CM_ "IMPORT _nissan_common.dbc";

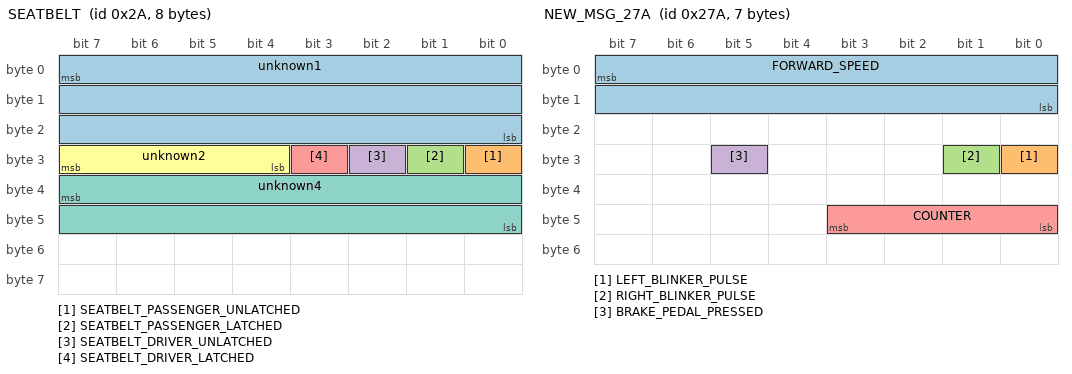
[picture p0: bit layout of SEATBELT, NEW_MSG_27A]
BO_ 42 SEATBELT: 8 XXX
 SG_ unknown1 : 7|24@0+ (1,0) [0|16777215] "" XXX
 SG_ SEATBELT_PASSENGER_UNLATCHED : 24|1@0+ (1,0) [0|1] "" XXX
 SG_ SEATBELT_PASSENGER_LATCHED : 25|1@0+ (1,0) [0|1] "" XXX
 SG_ SEATBELT_DRIVER_UNLATCHED : 26|1@0+ (1,0) [0|1] "" XXX
 SG_ SEATBELT_DRIVER_LATCHED : 27|1@1+ (1,0) [0|3] "" XXX
 SG_ unknown2 : 31|4@0+ (1,0) [0|15] "" XXX
 SG_ unknown4 : 39|16@0+ (1,0) [0|65535] "" XXX

BO_ 634 NEW_MSG_27A: 7 XXX
 SG_ FORWARD_SPEED : 7|16@0+ (0.1,0) [0|65535] "KPH" XXX
 SG_ LEFT_BLINKER_PULSE : 24|1@0+ (1,0) [0|1] "" XXX
 SG_ RIGHT_BLINKER_PULSE : 25|1@0+ (1,0) [0|1] "" XXX
 SG_ BRAKE_PEDAL_PRESSED : 29|1@0+ (1,0) [0|1] "" XXX
 SG_ COUNTER : 40|4@1+ (1,0) [0|15] "" XXX

BO_ 460 BRAKE_PEDAL: 8 XXX
 SG_ BRAKE_PEDAL : 7|8@0+ (1,0) [0|256] "" XXX

BO_ 569 CRUISE_THROTTLE: 8 XXX
 SG_ GAS_PEDAL_INVERTED : 15|8@0+ (1,0) [0|255] "" XXX
 SG_ GAS_PEDAL : 7|8@0+ (1,0) [0|255] "" XXX
 SG_ CRUISE_AVAILABLE : 17|1@0+ (1,0) [0|1] "" XXX
 SG_ unsure1 : 23|6@0+ (1,0) [0|63] "" XXX
 SG_ unsure2 : 16|1@0+ (1,0) [0|1] "" XXX
 SG_ unsure3 : 31|2@0+ (1,0) [0|3] "" XXX
 SG_ NO_BUTTON_PRESSED : 29|1@0+ (1,0) [0|1] "" XXX
 SG_ RES_BUTTON : 28|1@0+ (1,0) [0|1] "" XXX
 SG_ SET_BUTTON : 27|1@0+ (1,0) [0|1] "" XXX
 SG_ FOLLOW_DISTANCE_BUTTON : 26|1@0+ (1,0) [0|1] "" XXX
 SG_ CANCEL_BUTTON : 25|1@0+ (1,0) [0|1] "" XXX
 SG_ PROPILOT_BUTTON : 24|1@0+ (1,0) [0|1] "" XXX
 SG_ USER_BRAKE_PRESSED : 37|1@0+ (1,0) [0|1] "" XXX
 SG_ COUNTER : 32|2@1+ (1,0) [0|3] "" XXX
 SG_ unsure5 : 47|8@0+ (1,0) [0|255] "" XXX
 SG_ unsure6 : 55|8@0+ (1,0) [0|255] "" XXX
 SG_ unsure7 : 63|8@0+ (1,0) [0|255] "" XXX

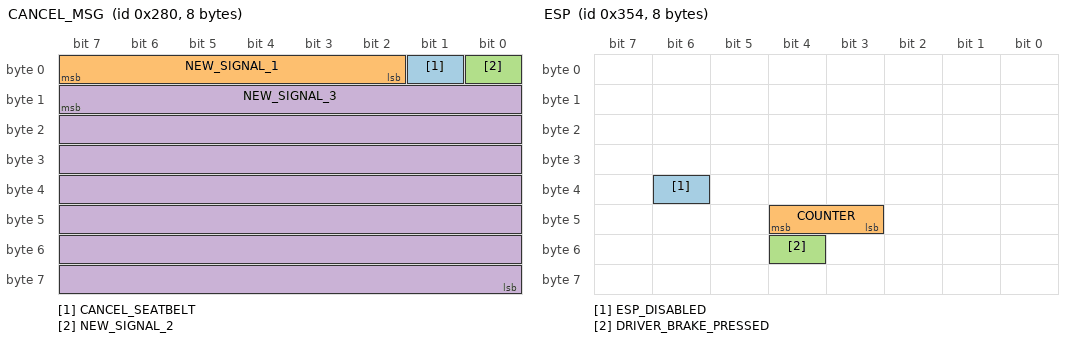
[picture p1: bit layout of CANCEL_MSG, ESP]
BO_ 640 CANCEL_MSG: 8 XXX
  SG_ CANCEL_SEATBELT : 1|1@0+ (1,0) [0|1] "" XXX
  SG_ NEW_SIGNAL_1 : 7|6@0+ (1,0) [0|63] "" XXX
  SG_ NEW_SIGNAL_2 : 0|1@0+ (1,0) [0|1] "" XXX
  SG_ NEW_SIGNAL_3 : 15|56@0+ (1,0) [0|72057594037927940] "" XXX

BO_ 1008 LEFT_BSW: 7 XXX
 SG_ WARNING_STATUS : 3|4@0+ (1,0) [0|15] "" XXX

BO_ 1011 RIGHT_BSW: 7 XXX
 SG_ WARNING_STATUS : 3|4@0+ (1,0) [0|15] "" XXX

BO_ 1856 ABS_QUERY: 8 XXX

BO_ 1859 BCM_QUERY: 8 XXX

BO_ 1860 HVAC_QUERY: 8 XXX

BO_ 1888 ABS_RESPONSE: 8 XXX

BO_ 1891 BCM_RESPONSE: 8 XXX

BO_ 1892 HVAC_RESPONSE: 8 XXX

BO_ 1943 VCM_QUERY: 8 XXX

BO_ 1946 VCM_RESPONSE: 8 XXX

BO_ 644 WHEEL_SPEEDS_FRONT: 8 XXX
 SG_ WHEEL_SPEED_FR : 7|16@0+ (0.005,0) [0|65535] "KPH" XXX
 SG_ WHEEL_SPEED_FL : 23|16@0+ (0.005,0) [0|65535] "KPH" XXX

BO_ 852 ESP: 8 XXX
 SG_ ESP_DISABLED : 38|1@0+ (1,0) [0|1] "" XXX
 SG_ COUNTER : 43|2@1+ (1,0) [0|3] "" XXX
 SG_ DRIVER_BRAKE_PRESSED : 52|1@0+ (1,0) [0|1] "" XXX

BO_ 853 HUD_SETTINGS: 8 XXX
 SG_ SPEED_MPH : 37|1@0+ (1,0) [0|1] "" XXX

BO_ 856 LIGHTS: 8 XXX
 SG_ LEFT_BLINKER : 17|1@0+ (1,0) [0|1] "" XXX
 SG_ RIGHT_BLINKER : 18|1@0+ (1,0) [0|1] "" XXX

BO_ 654 NEW_MSG_28E: 6 XXX
 SG_ PROPILOT_BRAKE_ACTIVE : 16|1@0+ (1,0) [0|1] "" XXX
 SG_ COUNTER : 41|2@1+ (1,0) [0|3] "" XXX

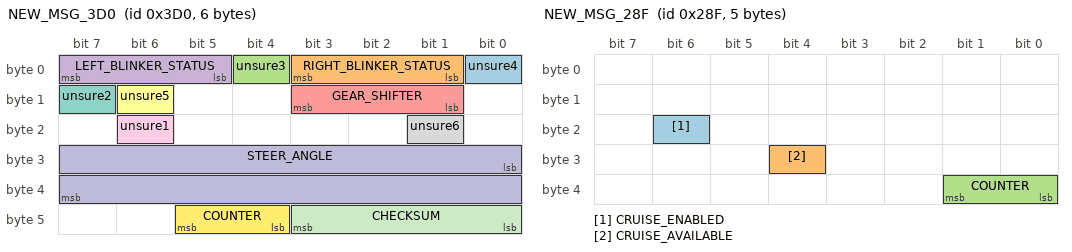
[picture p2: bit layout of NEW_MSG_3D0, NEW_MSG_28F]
BO_ 976 NEW_MSG_3D0: 6 XXX
 SG_ unsure4 : 0|1@0+ (1,0) [0|1] "" XXX
 SG_ RIGHT_BLINKER_STATUS : 3|3@0+ (1,0) [0|7] "" XXX
 SG_ unsure3 : 4|1@0+ (1,0) [0|1] "" XXX
 SG_ LEFT_BLINKER_STATUS : 5|3@1+ (1,0) [0|7] "" XXX
 SG_ GEAR_SHIFTER : 9|3@1+ (1,0) [0|7] "" XXX
 SG_ unsure5 : 14|1@0+ (1,0) [0|1] "" XXX
 SG_ unsure2 : 15|1@0+ (1,0) [0|1] "" XXX
 SG_ unsure6 : 17|1@0+ (1,0) [0|1] "" XXX
 SG_ unsure1 : 22|1@0+ (1,0) [0|1] "" XXX
 SG_ STEER_ANGLE : 24|16@1- (-0.1,0) [0|65535] "deg" XXX
 SG_ CHECKSUM : 43|4@0+ (1,0) [0|15] "" XXX
 SG_ COUNTER : 44|2@1+ (1,0) [0|3] "" XXX

BO_ 1057 GEARBOX: 3 XXX
 SG_ GEAR_SHIFTER : 5|3@0+ (1,0) [0|255] "" XXX

BO_ 655 NEW_MSG_28F: 5 XXX
 SG_ CRUISE_ENABLED : 22|1@0+ (1,0) [0|1] "" XXX
 SG_ CRUISE_AVAILABLE : 28|1@0+ (1,0) [0|1] "" XXX
 SG_ COUNTER : 32|2@1+ (1,0) [0|3] "" XXX

BO_ 724 NEW_MSG_2D4: 6 XXX
 SG_ COUNTER : 33|2@0+ (1,0) [0|3] "" XXX
 SG_ CRUISE_ENABLED : 39|1@0+ (1,0) [0|1] "" XXX

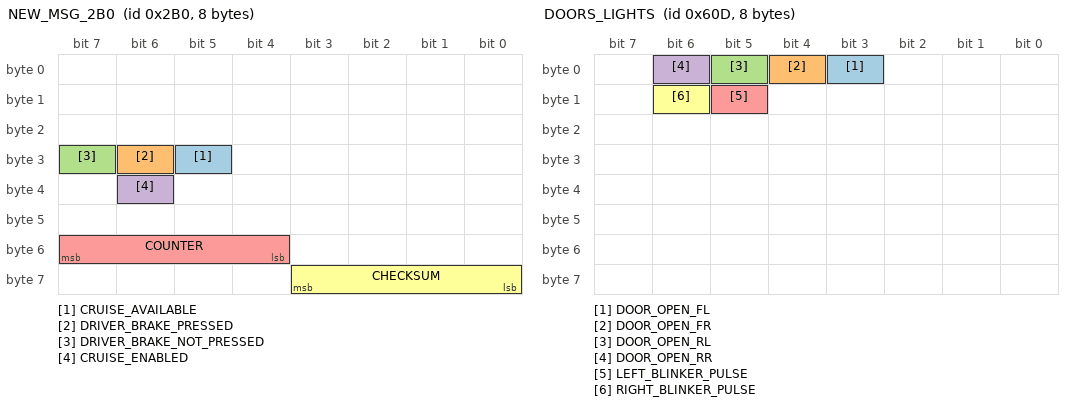
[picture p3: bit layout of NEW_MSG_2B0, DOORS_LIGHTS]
BO_ 688 NEW_MSG_2B0: 8 XXX
 SG_ CRUISE_AVAILABLE : 29|1@0+ (1,0) [0|1] "" XXX
 SG_ DRIVER_BRAKE_PRESSED : 30|1@0+ (1,0) [0|1] "" XXX
 SG_ DRIVER_BRAKE_NOT_PRESSED : 31|1@0+ (1,0) [0|1] "" XXX
 SG_ CRUISE_ENABLED : 38|1@0+ (1,0) [0|1] "" XXX
 SG_ COUNTER : 52|4@1+ (1,0) [0|15] "" XXX
 SG_ CHECKSUM : 59|4@0+ (1,0) [0|15] "" XXX

BO_ 1549 DOORS_LIGHTS: 8 XXX
 SG_ DOOR_OPEN_FL : 3|1@0+ (1,0) [0|1] "" XXX
 SG_ DOOR_OPEN_FR : 4|1@0+ (1,0) [0|1] "" XXX
 SG_ DOOR_OPEN_RL : 5|1@0+ (1,0) [0|1] "" XXX
 SG_ DOOR_OPEN_RR : 6|1@0+ (1,0) [0|1] "" XXX
 SG_ LEFT_BLINKER_PULSE : 13|1@0+ (1,0) [0|1] "" XXX
 SG_ RIGHT_BLINKER_PULSE : 14|1@0+ (1,0) [0|1] "" XXX

VAL_ 976 RIGHT_BLINKER_STATUS 3 "Off" 1 "On";
VAL_ 976 LEFT_BLINKER_STATUS 3 "Off" 1 "On";
VAL_ 976 GEAR_SHIFTER 7 "B" 4 "D" 3 "N" 2 "R" 1 "P";
VAL_ 1008 WARNING_STATUS 13 "LIT_INDICATOR" 0 "UNLIT_INDICATOR" 5 "FLASH_INDICATOR";
VAL_ 1011 WARNING_STATUS 13 "LIT_INDICATOR" 0 "UNLIT_INDICATOR" 5 "FLASH_INDICATOR";
VAL_ 1057 GEAR_SHIFTER 7 "B" 4 "D" 3 "N" 2 "R" 1 "P" ;
